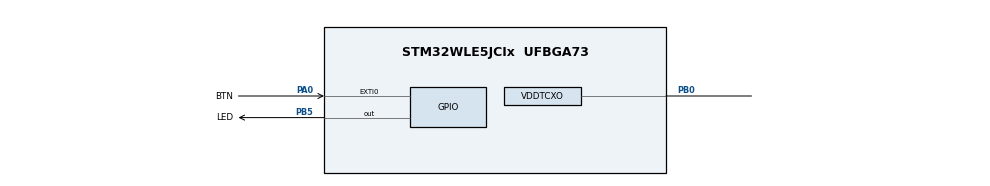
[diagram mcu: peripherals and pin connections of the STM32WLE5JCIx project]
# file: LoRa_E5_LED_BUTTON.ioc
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Mcu.Family=STM32WL
PC15-OSC32_OUT.Mode=LSE-External-Oscillator
PA0.GPIO_Label=BTN
PC14-OSC32_IN.Signal=RCC_OSC32_IN
ProjectManager.StackSize=0x400
PA13.Signal=DEBUG_JTMS-SWDIO
ProjectManager.TargetToolchain=STM32CubeIDE
PB0-VDD_TCXO.Mode=HSE-TCXO
PB5.PinState=GPIO_PIN_RESET
OSC_IN.Signal=RCC_OSC_IN
RCC.LSE_VALUE=32768
PC15-OSC32_OUT.Signal=RCC_OSC32_OUT
RCC.HSE_VALUE=8000000
board=custom
RCC.VCOOutputFreq_Value=32000000
PC14-OSC32_IN.Mode=LSE-External-Oscillator
PA14.Mode=Serial_Wire
PA0.GPIO_ModeDefaultEXTI=GPIO_MODE_IT_FALLING
PB0-VDD_TCXO.Signal=VDDTCXO
PA13.Mode=Serial_Wire
Mcu.Name=STM32WLE5JCIx
PA0.Signal=GPXTI0
NVIC.EXTI0_IRQn=true\:0\:0\:false\:false\:true\:true\:true
Mcu.Package=UFBGA73
PB5.Signal=GPIO_Output
OSC_IN.Mode=HSE-TCXO
PB5.GPIO_PuPd=GPIO_NOPULL
PA0.GPIO_PuPd=GPIO_PULLUP
PA14.Signal=DEBUG_JTCK-SWCLK
ProjectManager.HeapSize=0x200
RCC.HSI_VALUE=16000000
NVIC.PriorityGroup=NVIC_PRIORITYGROUP_4
PB5.GPIO_Label=LED

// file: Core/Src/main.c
/* USER CODE BEGIN Header */
/**
  ******************************************************************************
  * @file           : main.c
  * @brief          : Main program body
  ******************************************************************************
  * @attention
  *
  * <h2><center>&copy; Copyright (c) 2021 STMicroelectronics.
  * All rights reserved.</center></h2>
  *
  * This software component is licensed by ST under BSD 3-Clause license,
  * the "License"; You may not use this file except in compliance with the
  * License. You may obtain a copy of the License at:
  *                        opensource.org/licenses/BSD-3-Clause
  *
  ******************************************************************************
  */
/* USER CODE END Header */
#include "main.h"
#include "gpio.h"

void SystemClock_Config(void);
/* USER CODE BEGIN PFP */

void HAL_GPIO_EXTI_Callback(uint16_t GPIO_Pin);

/* USER CODE END PFP */

int main(void)
{

  /* MCU Configuration--------------------------------------------------------*/

  /* Reset of all peripherals, Initializes the Flash interface and the Systick. */
  HAL_Init();

  /* Configure the system clock */
  SystemClock_Config();

  /* Initialize all configured peripherals */
  MX_GPIO_Init();

  /* Infinite loop */
  while (1)
  {

    /* USER CODE BEGIN 3 */
	  __WFI();
  }
  /* USER CODE END 3 */
}

void SystemClock_Config(void)
{
  RCC_OscInitTypeDef RCC_OscInitStruct = {0};
  RCC_ClkInitTypeDef RCC_ClkInitStruct = {0};

  /** Configure LSE Drive Capability
  */
  HAL_PWR_EnableBkUpAccess();
  __HAL_RCC_LSEDRIVE_CONFIG(RCC_LSEDRIVE_LOW);
  /** Configure the main internal regulator output voltage
  */
  __HAL_PWR_VOLTAGESCALING_CONFIG(PWR_REGULATOR_VOLTAGE_SCALE2);
  /** Initializes the CPU, AHB and APB busses clocks
  */
  RCC_OscInitStruct.OscillatorType = RCC_OSCILLATORTYPE_LSE|RCC_OSCILLATORTYPE_MSI;
  RCC_OscInitStruct.LSEState = RCC_LSE_ON;
  RCC_OscInitStruct.MSIState = RCC_MSI_ON;
  RCC_OscInitStruct.MSICalibrationValue = RCC_MSICALIBRATION_DEFAULT;
  RCC_OscInitStruct.MSIClockRange = RCC_MSIRANGE_6;
  RCC_OscInitStruct.PLL.PLLState = RCC_PLL_NONE;
  if (HAL_RCC_OscConfig(&RCC_OscInitStruct) != HAL_OK)
  {
    Error_Handler();
  }
  /** Configure the SYSCLKSource, HCLK, PCLK1 and PCLK2 clocks dividers
  */
  RCC_ClkInitStruct.ClockType = RCC_CLOCKTYPE_HCLK3|RCC_CLOCKTYPE_HCLK
                              |RCC_CLOCKTYPE_SYSCLK|RCC_CLOCKTYPE_PCLK1
                              |RCC_CLOCKTYPE_PCLK2;
  RCC_ClkInitStruct.SYSCLKSource = RCC_SYSCLKSOURCE_MSI;
  RCC_ClkInitStruct.AHBCLKDivider = RCC_SYSCLK_DIV1;
  RCC_ClkInitStruct.APB1CLKDivider = RCC_HCLK_DIV1;
  RCC_ClkInitStruct.APB2CLKDivider = RCC_HCLK_DIV1;
  RCC_ClkInitStruct.AHBCLK3Divider = RCC_SYSCLK_DIV1;

  if (HAL_RCC_ClockConfig(&RCC_ClkInitStruct, FLASH_LATENCY_0) != HAL_OK)
  {
    Error_Handler();
  }
}

/* USER CODE BEGIN 4 */
void HAL_GPIO_EXTI_Callback(uint16_t GPIO_Pin){
	if(GPIO_Pin == BTN_Pin){
		HAL_GPIO_TogglePin(LED_GPIO_Port, LED_Pin);
	}
}
/* USER CODE END 4 */

void Error_Handler(void)
{
  __disable_irq();
  while (1)
  {
  }
}

/************************ (C) COPYRIGHT STMicroelectronics *****END OF FILE****/
